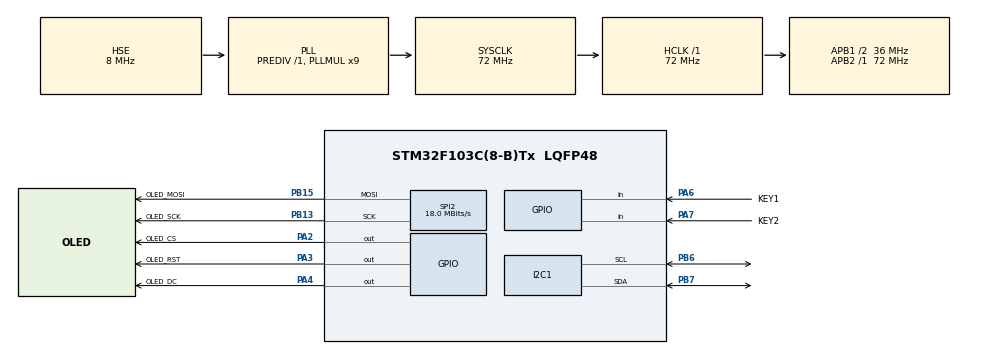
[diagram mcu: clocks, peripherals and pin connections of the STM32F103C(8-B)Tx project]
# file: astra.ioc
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ADC1.Channel-0\#ChannelRegularConversion=ADC_CHANNEL_TEMPSENSOR
ADC1.NbrOfConversionFlag=1
ADC1.Rank-0\#ChannelRegularConversion=1
ADC1.SamplingTime-0\#ChannelRegularConversion=ADC_SAMPLETIME_1CYCLE_5
ADC1.master=1
Dma.I2C1_TX.1.Direction=DMA_MEMORY_TO_PERIPH
Dma.I2C1_TX.1.Instance=DMA1_Channel6
Dma.I2C1_TX.1.MemDataAlignment=DMA_MDATAALIGN_BYTE
Dma.I2C1_TX.1.MemInc=DMA_MINC_ENABLE
Dma.I2C1_TX.1.Mode=DMA_NORMAL
Dma.I2C1_TX.1.PeriphDataAlignment=DMA_PDATAALIGN_BYTE
Dma.I2C1_TX.1.PeriphInc=DMA_PINC_DISABLE
Dma.I2C1_TX.1.Priority=DMA_PRIORITY_LOW
Dma.Request0=SPI2_TX
Dma.Request1=I2C1_TX
Dma.SPI2_TX.0.Direction=DMA_MEMORY_TO_PERIPH
Dma.SPI2_TX.0.Instance=DMA1_Channel5
Dma.SPI2_TX.0.MemDataAlignment=DMA_MDATAALIGN_BYTE
Dma.SPI2_TX.0.MemInc=DMA_MINC_ENABLE
Dma.SPI2_TX.0.Mode=DMA_NORMAL
Dma.SPI2_TX.0.PeriphDataAlignment=DMA_PDATAALIGN_BYTE
Dma.SPI2_TX.0.PeriphInc=DMA_PINC_DISABLE
Dma.SPI2_TX.0.Priority=DMA_PRIORITY_LOW
I2C1.I2C_Mode=I2C_Fast
Mcu.Family=STM32F1
Mcu.Name=STM32F103C(8-B)Tx
Mcu.Package=LQFP48
NVIC.DMA1_Channel5_IRQn=true\:0\:0\:false\:false\:true\:false\:true\:true
NVIC.DMA1_Channel6_IRQn=true\:0\:0\:false\:false\:true\:false\:true\:true
NVIC.PriorityGroup=NVIC_PRIORITYGROUP_4
NVIC.SPI2_IRQn=true\:0\:0\:false\:false\:true\:true\:true\:true
PA13.Mode=Serial_Wire
PA13.Signal=SYS_JTMS-SWDIO
PA14.Mode=Serial_Wire
PA14.Signal=SYS_JTCK-SWCLK
PA2.GPIO_Label=OLED_CS
PA2.GPIO_PuPd=GPIO_PULLDOWN
PA2.Signal=GPIO_Output
PA3.GPIO_Label=OLED_RST
PA3.GPIO_PuPd=GPIO_PULLUP
PA3.GPIO_Speed=GPIO_SPEED_FREQ_HIGH
PA3.PinState=GPIO_PIN_SET
PA3.Signal=GPIO_Output
PA4.GPIO_Label=OLED_DC
PA4.GPIO_PuPd=GPIO_PULLUP
PA4.GPIO_Speed=GPIO_SPEED_FREQ_HIGH
PA4.PinState=GPIO_PIN_SET
PA4.Signal=GPIO_Output
PA6.GPIO_Label=KEY1
PA6.Signal=GPIO_Input
PA7.GPIO_Label=KEY2
PA7.Signal=GPIO_Input
PB13.GPIO_Label=OLED_SCK
PB13.Mode=TX_Only_Simplex_Unidirect_Master
PB13.Signal=SPI2_SCK
PB15.GPIO_Label=OLED_MOSI
PB15.Mode=TX_Only_Simplex_Unidirect_Master
PB15.Signal=SPI2_MOSI
PB6.Mode=I2C
PB6.Signal=I2C1_SCL
PB7.Mode=I2C
PB7.Signal=I2C1_SDA
PD0-OSC_IN.Mode=HSE-External-Oscillator
PD0-OSC_IN.Signal=RCC_OSC_IN
PD1-OSC_OUT.Mode=HSE-External-Oscillator
PD1-OSC_OUT.Signal=RCC_OSC_OUT
ProjectManager.HeapSize=0x100
ProjectManager.StackSize=0x100
ProjectManager.TargetToolchain=STM32CubeIDE
RCC.ADCPresc=RCC_ADCPCLK2_DIV6
RCC.AHBFreq_Value=72000000
RCC.APB1CLKDivider=RCC_HCLK_DIV2
RCC.APB1Freq_Value=36000000
RCC.APB1TimFreq_Value=72000000
RCC.APB2Freq_Value=72000000
RCC.APB2TimFreq_Value=72000000
RCC.HCLKFreq_Value=72000000
RCC.PLLMUL=RCC_PLL_MUL9
RCC.PLLSourceVirtual=RCC_PLLSOURCE_HSE
RCC.SYSCLKFreq_VALUE=72000000
RCC.SYSCLKSource=RCC_SYSCLKSOURCE_PLLCLK
RCC.USBFreq_Value=72000000
SPI2.BaudRatePrescaler=SPI_BAUDRATEPRESCALER_2
SPI2.CLKPhase=SPI_PHASE_2EDGE
SPI2.CLKPolarity=SPI_POLARITY_HIGH
SPI2.CalculateBaudRate=18.0 MBits/s
SPI2.Direction=SPI_DIRECTION_2LINES
SPI2.Mode=SPI_MODE_MASTER
SPI2.VirtualType=VM_MASTER
VP_ADC1_TempSens_Input.Mode=IN-TempSens
board=custom

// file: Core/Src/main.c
/* USER CODE BEGIN Header */
/**
  ******************************************************************************
  * @file           : main.c
  * @brief          : Main program body
  ******************************************************************************
  * @attention
  *
  * Copyright (c) 2024 STMicroelectronics.
  * All rights reserved.
  *
  * This software is licensed under terms that can be found in the LICENSE file
  * in the root directory of this software component.
  * If no LICENSE file comes with this software, it is provided AS-IS.
  *
  ******************************************************************************
  */
/* USER CODE END Header */
#include "main.h"
#include "adc.h"
#include "dma.h"
#include "i2c.h"
#include "spi.h"
#include "gpio.h"

/* USER CODE BEGIN Includes */
#include "astra/astra_rocket.h"
/* USER CODE END Includes */

void SystemClock_Config(void);

int main(void)
{

  /* MCU Configuration--------------------------------------------------------*/

  /* Reset of all peripherals, Initializes the Flash interface and the Systick. */
  HAL_Init();

  /* Configure the system clock */
  SystemClock_Config();

  /* Initialize all configured peripherals */
  MX_GPIO_Init();
  MX_DMA_Init();
  MX_SPI2_Init();
  MX_ADC1_Init();
  MX_I2C1_Init();
  /* USER CODE BEGIN 2 */
  astraCoreInit();
  astraCoreStart();
  /* USER CODE END 2 */

  /* Infinite loop */
  /* USER CODE BEGIN WHILE */
  while (1)
  {
    HAL_Delay(1);
    /* USER CODE END WHILE */

  }
}

void SystemClock_Config(void)
{
  RCC_OscInitTypeDef RCC_OscInitStruct = {0};
  RCC_ClkInitTypeDef RCC_ClkInitStruct = {0};
  RCC_PeriphCLKInitTypeDef PeriphClkInit = {0};

  /** Initializes the RCC Oscillators according to the specified parameters
  * in the RCC_OscInitTypeDef structure.
  */
  RCC_OscInitStruct.OscillatorType = RCC_OSCILLATORTYPE_HSE;
  RCC_OscInitStruct.HSEState = RCC_HSE_ON;
  RCC_OscInitStruct.HSEPredivValue = RCC_HSE_PREDIV_DIV1;
  RCC_OscInitStruct.HSIState = RCC_HSI_ON;
  RCC_OscInitStruct.PLL.PLLState = RCC_PLL_ON;
  RCC_OscInitStruct.PLL.PLLSource = RCC_PLLSOURCE_HSE;
  RCC_OscInitStruct.PLL.PLLMUL = RCC_PLL_MUL9;
  if (HAL_RCC_OscConfig(&RCC_OscInitStruct) != HAL_OK)
  {
    Error_Handler();
  }

  /** Initializes the CPU, AHB and APB buses clocks
  */
  RCC_ClkInitStruct.ClockType = RCC_CLOCKTYPE_HCLK|RCC_CLOCKTYPE_SYSCLK
                              |RCC_CLOCKTYPE_PCLK1|RCC_CLOCKTYPE_PCLK2;
  RCC_ClkInitStruct.SYSCLKSource = RCC_SYSCLKSOURCE_PLLCLK;
  RCC_ClkInitStruct.AHBCLKDivider = RCC_SYSCLK_DIV1;
  RCC_ClkInitStruct.APB1CLKDivider = RCC_HCLK_DIV2;
  RCC_ClkInitStruct.APB2CLKDivider = RCC_HCLK_DIV1;

  if (HAL_RCC_ClockConfig(&RCC_ClkInitStruct, FLASH_LATENCY_2) != HAL_OK)
  {
    Error_Handler();
  }
  PeriphClkInit.PeriphClockSelection = RCC_PERIPHCLK_ADC;
  PeriphClkInit.AdcClockSelection = RCC_ADCPCLK2_DIV6;
  if (HAL_RCCEx_PeriphCLKConfig(&PeriphClkInit) != HAL_OK)
  {
    Error_Handler();
  }
}

void Error_Handler(void)
{
  __disable_irq();
  while (1)
  {
  }
}
